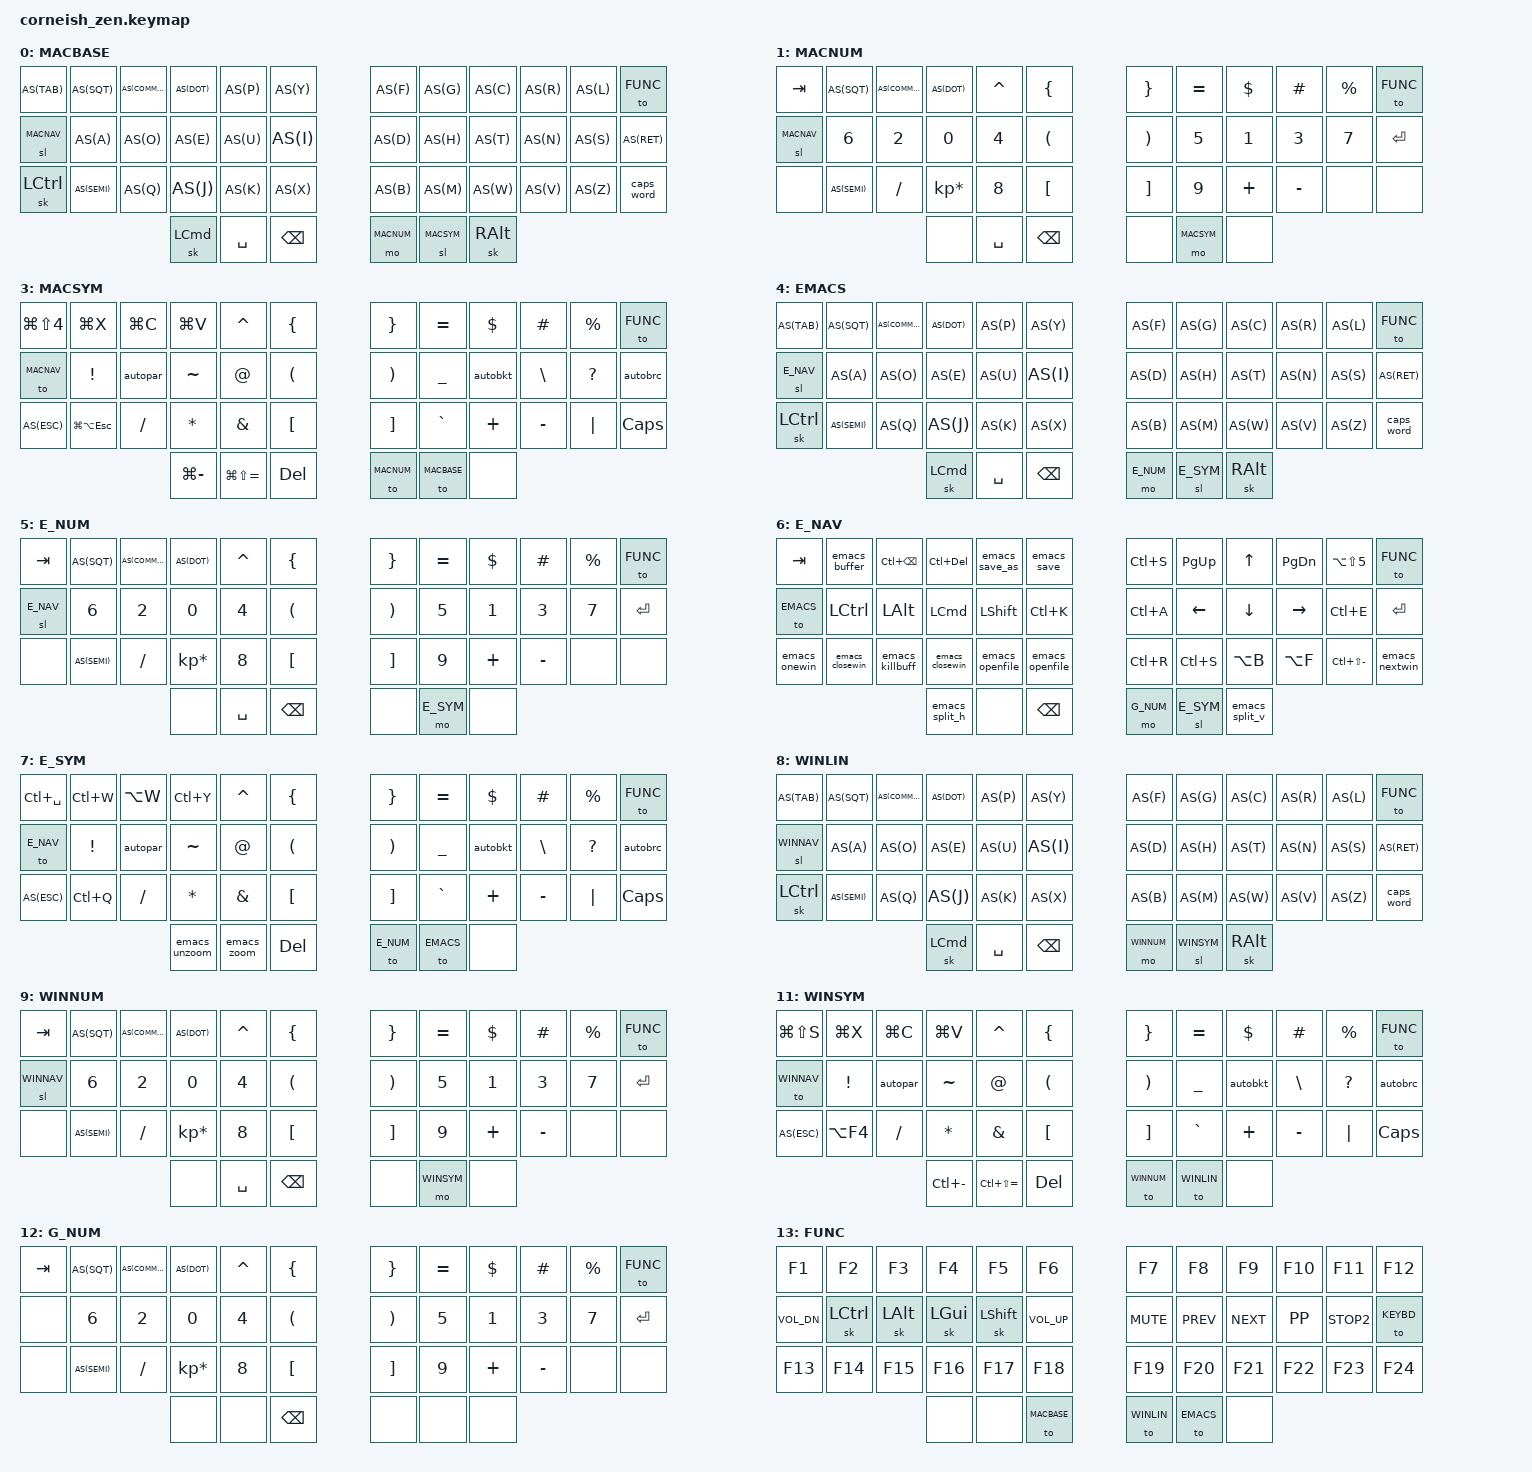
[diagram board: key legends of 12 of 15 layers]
/*
*
* Copyright (c) 2021 Darryl deHaan
* SPDX-License-Identifier: MIT
*
*/

#include <behaviors.dtsi>
#include <dt-bindings/zmk/keys.h>
#include <dt-bindings/zmk/bt.h>
#define MACBASE 0
#define MACNUM 1
#define MACNAV 2
#define MACSYM 3
#define EMACS 4
#define E_NUM 5
#define E_NAV 6
#define E_SYM 7
#define WINLIN 8
#define WINNUM 9
#define WINNAV 10
#define WINSYM 11
#define G_NUM 12
#define FUNC 13
#define KEYBD 14

#define AS(keycode) &as LS(keycode) keycode     // Autoshift Macro





/ {
  chosen {
    zmk,matrix_transform = &default_transform;
    //zmk,matrix_transform = &five_column_transform;
  };
};

 / {  // MACROS
     ZMK_MACRO(emacs_save,
        wait-ms = <30>;
        tap-ms = <40>;
        bindings = < &kp LC(X) &kp LC(S) >;
    )

     ZMK_MACRO(emacs_buffer,
        wait-ms = <30>;
        tap-ms = <40>;
        bindings = < &kp LC(X) &kp B >;
    )

     ZMK_MACRO(emacs_save_as,
        wait-ms = <30>;
        tap-ms = <40>;
        bindings = < &kp LC(X) &kp LC(W) >;
    )

     ZMK_MACRO(emacs_unzoom,
        wait-ms = <30>;
        tap-ms = <40>;
        bindings = < &kp LC(X) &kp LC(MINUS) &kp LC(G) >;
    )

     ZMK_MACRO(emacs_zoom,
        wait-ms = <30>;
        tap-ms = <40>;
        bindings = < &kp LC(X) &kp LC(LS(EQUAL)) &kp LC(G) >;
    )


     ZMK_MACRO(emacs_closewin,
        wait-ms = <30>;
        tap-ms = <40>;
        bindings = < &kp LC(X) &kp N0 >;
    )

     ZMK_MACRO(emacs_killbuff,
        wait-ms = <30>;
        tap-ms = <40>;
        bindings = < &kp LC(X) &kp K >;
    )

     ZMK_MACRO(emacs_openfile,
        wait-ms = <30>;
        tap-ms = <40>;
        bindings = < &kp LC(X) &kp LC(F) >;
    )

ZMK_MACRO(emacs_onewin,
wait-ms = <30>;
tap-ms = <40>;
bindings = < &kp LC(X) &kp N1 >;
)


     ZMK_MACRO(emacs_nextwin,
        wait-ms = <30>;
        tap-ms = <40>;
        bindings = < &kp LC(X) &kp O >;
    )

     ZMK_MACRO(emacs_split_h,
        wait-ms = <30>;
        tap-ms = <40>;
        bindings = < &kp LC(X) &kp N2 >;
    )

     ZMK_MACRO(win_del_line,
        wait-ms = <30>;
        tap-ms = <40>;
        bindings = < &kp LS(END) &kp DEL >;
    )



     ZMK_MACRO(emacs_split_v,
        wait-ms = <30>;
        tap-ms = <40>;
        bindings = < &kp LC(X) &kp N3 >;
    )



    ZMK_MACRO(autobrc,
        wait-ms = <30>;
        tap-ms = <40>;
        bindings = < &kp LBRC &kp RBRC &kp LEFT >;
    )

     ZMK_MACRO(autopar,
        wait-ms = <30>;
        tap-ms = <40>;
        bindings = < &kp LPAR &kp RPAR &kp LEFT  >;
    )

     ZMK_MACRO(autobkt,
        wait-ms = <30>;
        tap-ms = <40>;
        bindings = < &kp LBKT &kp RBKT &kp LEFT >;
    )

     ZMK_MACRO(vlog_assign,
        wait-ms = <30>;
        tap-ms = <40>;
        bindings = < &kp LT &kp EQUAL >;
    )

     

};


/ {

 behaviors {
        as: auto_shift {
            compatible = "zmk,behavior-hold-tap";
            label = "AUTO_SHIFT";
            #binding-cells = <2>;
            tapping_term_ms = <210>;
            quick_tap_ms = <0>;
            flavor = "tap-preferred";
            bindings = <&kp>, <&kp>;
        };
    };


        keymap {
                compatible = "zmk,keymap";

                macbase_layer {
                        label = "MACBASE"; // layer 0
// notes: i want the nav layer activated as momentary or one-shot, not toggle, unless sent there by another laye0r
//        func should be a 'to' switch to that layer, but will consider osl at a later time
//        num should be momentary switch over
//        sym should be one shot layer
// -----------------------------------------------------------------------------------------
// | TAB   |  '  |  ,   |  .    |  P  |  Y   |   |  F    |  G    |  C  |  R  |  L  | L:FNC |
// | L:NAV |  A  |  O   |  E    |  U  |  I   |   |  D    |  H    |  T  |  N  |  S  | RET   |
// | CTRL  |  ;  |  Q   |  J    |  K  |  X   |   |  B    |  M    |  W  |  V  |  Z  | CMD   |
//                      | LCTRL | SPC | BSPC |   | L:NUM | L:SYM | ALT |
   bindings = <
   AS(TAB)     AS(SQT)  AS(COMMA) AS(DOT)   AS(P)     AS(Y)      AS(F)      AS(G)    AS(C)   AS(R)   AS(L)    &to FUNC
   &sl MACNAV  AS(A)    AS(O)     AS(E)     AS(U)     AS(I)      AS(D)      AS(H)    AS(T)   AS(N)   AS(S)    AS(RET)
   &sk LCTRL     AS(SEMI) AS(Q)     AS(J)     AS(K)     AS(X)      AS(B)      AS(M)    AS(W)   AS(V)   AS(Z)    &caps_word
                        &sk LCMD &kp SPACE &kp BSPC &mo MACNUM &sl MACSYM &sk RALT
                        >;
                };
                macnum_layer {
                        label = "MACNUM"; // layer 1
// -----------------------------------------------------------------------------------------
// | TAB   |  '  |  ,  |  .     |  ^  | {    |   | }    | =     |  $   |  #  |  %   | L:FNC |
// | L:NAV |  6  |  2  |  0     |  4  | (    |   | )    | 5     |  1   |  3  |  7   | RET    |
// | NONE  |  ;  |  /  |  *     |  8  | [    |   | ]    | 9     |  +   |  -  | NONE | NONE   |
//                     | NONE   | SPC | BSPC |   | NONE | 3:SYM | NONE |
   bindings = <
   &kp TAB    AS(SQT)  AS(COMMA) AS(DOT)          &kp CARET   &kp LBRC    &kp RBRC   &kp EQUAL  &kp DLLR &kp HASH  &kp PRCNT &to FUNC
   &sl MACNAV &kp N6   &kp N2    &kp N0           &kp N4      &kp LPAR    &kp RPAR   &kp N5     &kp N1   &kp N3    &kp N7    &kp RET
   &none      AS(SEMI) &kp FSLH  &kp KP_MULTIPLY  &kp N8      &kp LBKT    &kp RBKT   &kp N9     &kp PLUS &kp MINUS &none     &none
                                 &none            &kp SPACE   &kp BSPC    &none      &mo MACSYM &none
                        >;
                };

                macnav_layer {
                        label ="MACNAV"; //layer 2
// -----------------------------------------------------------------------------------------
// | TAB    | BUFFER | DEL WORD LFT| DEL WORD RGT | SAVEAS  | SAVE   |  | FIND       | PAGEUP    | UP         | PAGEDOWN   | REPLACE | L:FUNC   |
// | L:BASE | LCTRL  | LALT        | LCMD         | LSHFT | DEL LINE |  | HOME       | LEFT      | DOWN       | RIGHT      | END     | ENTER    |
// | MAX    | MIN    | CLOSE       | MINIMIZE     | NEW   | OPEN     |  | FIND REV   | FIND FWD  | WORD LEFT  | WORD RIGHT | UNDO    | NEXT WIN |
//                                 | WIN LEFT     | SPC   | DEL      |  | L:NUM      | L:SYM     | WIN RIGHT  |
                        bindings = <
   &kp TAB       &kp LG(O)  &kp LA(BSPC)  &kp LS(LA(DEL))      &kp LG(S)   &kp LG(LS(S)) &kp LG(F)     &kp PG_UP    &kp UP                &kp PG_DN     &kp LC(K)     &to FUNC
   &to MACBASE   &kp LCTRL  &kp LALT      &kp LCMD             &kp LSHFT   &kp LC(K)     &kp LG(LEFT)  &kp LEFT     &kp DOWN              &kp RIGHT     &kp LG(RIGHT) &kp RET
   &kp LA(LG(H)) &kp LG(H)  &kp LG(W)     &kp LG(M)            &kp LG(O)   &kp LG(N)     &kp LG(G)     &kp LA(LEFT) &kp LA(RIGHT)         &kp LG(LS(G)) &kp LG(Z)     &kp LC(F3)
                    	                  &kp LG(LA(LC(LEFT))) &kp LG(SPC) &kp BSPC      &mo G_NUM     &sl MACSYM   &kp LG(LA(LC(RIGHT)))
                        >;
                };
		
                macsym_layer {
                        label = "MACSYM"; //layer 3
// -----------------------------------------------------------------------------------------
// | SNIP  | CUT  | COPY| PASTE| ^    | {   | | }     |  =     |  $    |  #  |  %    | L:FUNC | 
// | L:NAV | !    | ()  |  ~   | @    | (   | | )     |  _     |  []   |  \  |  ?    | {}     |
// | ESC   | QUIT | /   |  *   | &    | [   | | ]     |  `     |  +    |  -  |  PIPE | CAPS   |
//                      | UNZM | ZOOM | DEL | | L:NUM | L:BASE | NONE  |
                        bindings = <
   &kp LG(LS(N4)) &kp LG(X)        &kp LG(C) &kp LG(V) &kp CARET  &kp LBRC &kp RBRC    &kp EQUAL   &kp DLLR &kp HASH  &kp PRCNT  &to FUNC
   &to MACNAV    &kp EXCL         &autopar  &kp TILDE &kp AT     &kp LPAR &kp RPAR    &kp UNDER   &autobkt &kp BSLH  &kp QMARK  &autobrc
   AS(ESC)       &kp LG(LA(ESC)) &kp FSLH  &kp STAR  &kp AMPS   &kp LBKT &kp RBKT    &kp GRAVE   &kp PLUS &kp MINUS &kp PIPE   &kp CAPS  
                    	          &kp LG(MINUS) &kp  LG(LS(EQUAL)) &kp DEL  &to MACNUM  &to MACBASE &none
                        >;
                };

// insert emacs and windows keyboards here

                emacs_layer {
                      label = "EMACS"; // layer 4
// notes: i want the nav layer activated as momentary or one-shot, not toggle, unless sent there by another laye0r
//        func should be a 'to' switch to that layer, but will consider osl at a later time
//        num should be momentary switch over
//        sym should be one shot layer
// -----------------------------------------------------------------------------------------
// | TAB   |  '  |  ,   |  .    |  P  |  Y   |   |  F    |  G    |  C  |  R  |  L  | L:FNC |
// | L:NAV |  A  |  O   |  E    |  U  |  I   |   |  D    |  H    |  T  |  N  |  S  | RET   |
// | CTRL  |  ;  |  Q   |  J    |  K  |  X   |   |  B    |  M    |  W  |  V  |  Z  |CapsWord|
//                      | LCMD  | SPC | BSPC |   | L:NUM | L:SYM | ALT |
   bindings = <
   AS(TAB)     AS(SQT)  AS(COMMA) AS(DOT)   AS(P)     AS(Y)      AS(F)      AS(G)    AS(C)   AS(R)   AS(L)    &to FUNC
   &sl E_NAV   AS(A)    AS(O)     AS(E)     AS(U)     AS(I)      AS(D)      AS(H)    AS(T)   AS(N)   AS(S)    AS(RET)
   &sk LCTRL   AS(SEMI) AS(Q)     AS(J)     AS(K)     AS(X)      AS(B)      AS(M)    AS(W)   AS(V)   AS(Z)    &caps_word
                        &sk LCMD &kp SPACE &kp BSPC &mo E_NUM &sl E_SYM &sk RALT
                        >;
                };
                e_num_layer {
                        label = "E_NUM"; // layer 5
// -----------------------------------------------------------------------------------------
// | TAB   |  '  |  ,  |  .     |  ^  | {    |   | }    | =     |  $   |  #  |  %   | L:FNC |
// | L:NAV |  6  |  2  |  0     |  4  | (    |   | )    | 5     |  1   |  3  |  7   | RET    |
// | ---   |  ;  |  /  |  *     |  8  | [    |   | ]    | 9     |  +   |  -  | NONE | NONE   |
//                     | MACRO1 | SPC | BSPC |   | NONE | 3:SYM |MACRO2|
   bindings = <
   &kp TAB    AS(SQT)  AS(COMMA) AS(DOT)          &kp CARET   &kp LBRC    &kp RBRC   &kp EQUAL &kp DLLR &kp HASH  &kp PRCNT &to FUNC
   &sl E_NAV  &kp N6   &kp N2    &kp N0           &kp N4      &kp LPAR    &kp RPAR   &kp N5    &kp N1   &kp N3    &kp N7    &kp RET
   &none    AS(SEMI) &kp FSLH  &kp KP_MULTIPLY  &kp N8      &kp LBKT    &kp RBKT   &kp N9    &kp PLUS &kp MINUS &none     &none
                                 &none            &kp SPACE   &kp BSPC    &none      &mo E_SYM &none
                        >;
                };

                e_nav_layer {
                        label = "E_NAV"; //layer 6
// -----------------------------------------------------------------------------------------------------------------------------------------------
// | TAB    | BUFFER | DEL WORD LFT| DEL WORD RGT | SAVEAS| SAVE     |  | FIND       | PAGEUP    | UP         | PAGEDOWN   | REPLACE | L:FUNC   |
// | L:BASE | LCTRL  | LALT        | LCMD         | LSHFT | DEL LINE |  | HOME       | LEFT      | DOWN       | RIGHT      | END     | ENTER    |
// | MAX    | MIN    | CLOSE       | MINIMIZE         | NEW   | OPEN     |  | FIND REV   | FIND FWD  | WORD LEFT  | WORD RIGHT | UNDO    | NEXT WIN |
//                                 | WIN LEFT     | SPC   | DEL      |  | L:NUM      | L:SYM     | WIN RIGHT  |
                        bindings = <
   &kp TAB       &emacs_buffer     &kp LC(BSPC)    &kp LC(DEL)      &emacs_save_as   &emacs_save     &kp LC(S)     &kp PG_UP    &kp UP                &kp PG_DN  &kp LA(LS(5))      &to FUNC
   &to EMACS     &kp LCTRL         &kp LALT        &kp LCMD         &kp LSHFT        &kp LC(K)       &kp LC(A)     &kp LEFT     &kp DOWN              &kp RIGHT  &kp LC(E)          &kp RET
   &emacs_onewin   &emacs_closewin      &emacs_killbuff &emacs_closewin  &emacs_openfile  &emacs_openfile &kp LC(R)     &kp LC(S)    &kp LA(B)             &kp LA(F)  &kp LC(LS(MINUS))  &emacs_nextwin
                    	                           &emacs_split_h   &none            &kp BSPC        &mo G_NUM     &sl E_SYM    &emacs_split_v
						   >;
                };
		
                e_sym_layer {
                        label = "E_SYM"; //layer 7
// -----------------------------------------------------------------------------------------
// | MARK     | CUT  | COPY  | PASTE | ^       | {   | | }     |  =     |  $   |  #  |  %    | L:FUNC | 
// | L:NAV    | !    | ()    |  ~    | @       | (   | | )     |  _     |  []  |  \  |  ?    | {}     |
// | ESC      | QUIT | /     |  *    | &       | [   | | ]     |  `     |  +   |  -  |  PIPE | CAPS   |
//                           | UNZOOM| ZOOM    | DEL | | L:NUM | L:BASE | NONE |
                        bindings = <
   &kp LC(SPC)  &kp LC(W)  &kp LA(W) &kp LC(Y) &kp CARET  &kp LBRC &kp RBRC    &kp EQUAL   &kp DLLR &kp HASH  &kp PRCNT  &to FUNC
   &to E_NAV    &kp EXCL   &autopar  &kp TILDE &kp AT     &kp LPAR &kp RPAR    &kp UNDER   &autobkt &kp BSLH  &kp QMARK  &autobrc
   AS(ESC)      &kp LC(Q)  &kp FSLH  &kp STAR  &kp AMPS   &kp LBKT &kp RBKT    &kp GRAVE   &kp PLUS &kp MINUS &kp PIPE   &kp CAPS
                    	             &emacs_unzoom    &emacs_zoom  &kp DEL  &to E_NUM   &to EMACS   &none
                        >;
                };

                winlin_layer {
                        label = "WINLIN"; // layer 8
// notes: i want the nav layer activated as momentary or one-shot, not toggle, unless sent there by another laye0r
//        func should be a 'to' switch to that layer, but will consider osl at a later time
//        num should be momentary switch over
//        sym should be one shot layer
// -----------------------------------------------------------------------------------------
// | TAB   |  '  |  ,   |  .    |  P  |  Y   |   |  F    |  G    |  C  |  R  |  L  | L:FNC |
// | L:NAV |  A  |  O   |  E    |  U  |  I   |   |  D    |  H    |  T  |  N  |  S  | RET   |
// | LCTRL |  ;  |  Q   |  J    |  K  |  X   |   |  B    |  M    |  W  |  V  |  Z  |Capsword|
//                      | LCMD  | SPC | BSPC |   | L:NUM | L:SYM | ALT |
   bindings = <
   AS(TAB)     AS(SQT)  AS(COMMA) AS(DOT)   AS(P)     AS(Y)      AS(F)      AS(G)    AS(C)   AS(R)   AS(L)    &to FUNC
   &sl WINNAV  AS(A)    AS(O)     AS(E)     AS(U)     AS(I)      AS(D)      AS(H)    AS(T)   AS(N)   AS(S)    AS(RET)
   &sk LCTRL   AS(SEMI) AS(Q)     AS(J)     AS(K)     AS(X)      AS(B)      AS(M)    AS(W)   AS(V)   AS(Z)    &caps_word
                        &sk LCMD  &kp SPACE &kp BSPC &mo WINNUM &sl WINSYM &sk RALT
                        >;
                };
                winnum_layer {
                        label = "WINNUM"; // layer 9
// -----------------------------------------------------------------------------------------
// | TAB   |  '  |  ,  |  .     |  ^  | {    |   | }    | =     |  $   |  #  |  %   | L:FNC |
// | L:NAV |  6  |  2  |  0     |  4  | (    |   | )    | 5     |  1   |  3  |  7   | RET    |
// |       |  ;  |  /  |  *     |  8  | [    |   | ]    | 9     |  +   |  -  | NONE | NONE   |
//                     | MACRO1 | SPC | BSPC |   | NONE | 3:SYM |MACRO2|
   bindings = <
   &kp TAB    AS(SQT)  AS(COMMA) AS(DOT)          &kp CARET   &kp LBRC    &kp RBRC   &kp EQUAL &kp DLLR &kp HASH  &kp PRCNT &to FUNC
   &sl WINNAV &kp N6   &kp N2    &kp N0           &kp N4      &kp LPAR    &kp RPAR   &kp N5    &kp N1   &kp N3    &kp N7    &kp RET
   &none      AS(SEMI) &kp FSLH  &kp KP_MULTIPLY  &kp N8      &kp LBKT    &kp RBKT   &kp N9    &kp PLUS &kp MINUS &none     &none
                                 &none            &kp SPACE   &kp BSPC    &none      &mo WINSYM &none
                        >;
                };

                winnav_layer {
                        label = "WINNAV"; //layer 10
// -----------------------------------------------------------------------------------------
// | TAB    | BUFFER | DEL WORD LFT| DEL WORD RGT | SAVEAS  | SAVE   |  | FIND       | PAGEDOWN  | UP         | PAGEUP     | REPLACE | L:FUNC   |
// | L:BASE | LCTRL  | LALT        | LCMD         | LSHFT | DEL LINE |  | HOME       | LEFT      | DOWN       | RIGHT      | END     | ENTER    |
// | MAX    | MIN    | CLOSE       | MINIMIZE     | NEW   | OPEN     |  | FIND REV   | FIND FWD  | WORD LEFT  | WORD RIGHT | UNDO    | NEXT WIN |
//                                 | WIN LEFT     | SPC   | DEL      |  | L:NUM      | L:SYM     | WIN RIGHT  |
                        bindings = <
   AS(TAB)       &kp LC(O)         &kp LC(BSPC)  &kp LC(DEL)          &kp F12     &kp LC(S)     &kp LC(F)          &kp PG_UP    &kp UP                &kp PG_DN     &kp LC(H)     &to FUNC
   &to WINLIN    &kp LCTRL         &kp LALT      &kp LCMD             &kp LSHFT   &win_del_line &kp HOME           &kp LEFT     &kp DOWN              &kp RIGHT     &kp END       &kp RET
   &kp LG(UP)    &kp LG(DOWN)      &kp LC(W)     &kp LG(DOWN)         &kp LC(N)   &kp LG(O)     &kp LC(LS(G))     &kp F3       &kp LC(LEFT)          &kp LC(RIGHT) &kp LC(Z)     &kp LA(LC(TAB))
                    	                         &kp LG(LA(LC(LEFT))) &kp LG(SPC) &kp BSPC      &mo G_NUM     &sl WINSYM   &kp LG(LA(LC(RIGHT)))
                        >;
                };
		
                winsym_layer {
                        label = "WINSYM"; //layer 11
// -----------------------------------------------------------------------------------------
// | SNIP     | CUT  | COPY  | PASTE | ^       | {   | | }     |  =     |  $   |  #  |  %    | L:FUNC | 
// | L:NAV    | !    | ()    |  ~    | @       | (   | | )     |  _     |  []  |  \  |  ?    | {}     |
// | ESC      | QUIT | /     |  *    | &       | [   | | ]     |  `     |  +   |  -  |  PIPE | CAPS   |
//                           | UNZM  | ZOOM    | DEL | | L:NUM | L:BASE | NONE |
                        bindings = <
   &kp LG(LS(S)) &kp LG(X)  &kp LG(C) &kp LG(V)     &kp CARET  &kp LBRC &kp RBRC    &kp EQUAL   &kp DLLR &kp HASH  &kp PRCNT  &to FUNC
   &to WINNAV    &kp EXCL   &autopar  &kp TILDE     &kp AT     &kp LPAR &kp RPAR    &kp UNDER   &autobkt &kp BSLH  &kp QMARK  &autobrc
   AS(ESC)       &kp LA(F4) &kp FSLH  &kp STAR      &kp AMPS   &kp LBKT &kp RBKT    &kp GRAVE   &kp PLUS &kp MINUS &kp PIPE   &kp CAPS
                    	              &kp LC(MINUS) &kp LC(LS(EQUAL)) &kp DEL  &to WINNUM   &to WINLIN   &none
                        >;
                };
                g_num_layer {
                        label = "G_NUM"; // layer 12
// -----------------------------------------------------------------------------------------
// | TAB  |  '  |  ,  |  .     |  ^  | {    |   | }    | =     |  $   |  #  |  %   | L:FNC |
// | NONE |  6  |  2  |  0     |  4  | (    |   | )    | 5     |  1   |  3  |  7   | RET    |
// | NONE |  ;  |  /  |  *     |  8  | [    |   | ]    | 9     |  +   |  -  | NONE | NONE   |
//                     | MACRO1 | SPC | BSPC |   | NONE | 3:SYM |MACRO2|
   bindings = <
   &kp TAB    AS(SQT)  AS(COMMA) AS(DOT)          &kp CARET   &kp LBRC    &kp RBRC   &kp EQUAL &kp DLLR &kp HASH  &kp PRCNT &to FUNC
   &none      &kp N6   &kp N2    &kp N0           &kp N4      &kp LPAR    &kp RPAR   &kp N5    &kp N1   &kp N3    &kp N7    &kp RET
   &none      AS(SEMI) &kp FSLH  &kp KP_MULTIPLY  &kp N8      &kp LBKT    &kp RBKT   &kp N9    &kp PLUS &kp MINUS &none     &none
                                 &none   &none    &kp BSPC    &none      &none     &none
                        >;
                };

                func_layer {
                        label = "FUNC"; //layer 13
// -----------------------------------------------------------------------------------------
// |  F1  |  F2  |  F3  | F4   | F5   |  F6   |  F7   |  F8      | F9  | F10 | F11 | F12  |  
// | VOLDN| LCTRL| LOPT | LCMD | LSHFT| VOLUP |  MUTE |  PREV    | NEXT| PLAY| STOP| KEYBD|
// | F13  | F14  | F15  | F16  | F17  | F18   |  F19  |  F20     | F21 | F22 | F23 |  F24 |  
//                      | NONE | NONE |MACBASE|WINBASE| EMACSBASE| NONE|
                        bindings = <
   &kp F1       &kp F2    &kp F3   &kp F4   &kp F5    &kp F6       &kp F7     &kp F8     &kp F9     &kp F10  &kp F11     &kp F12
   &kp K_VOL_DN &sk LCTRL &sk LALT &sk LGUI &sk LSHFT &kp K_VOL_UP &kp K_MUTE &kp K_PREV &kp K_NEXT &kp K_PP &kp K_STOP2 &to KEYBD
   &kp F13      &kp F14   &kp F15  &kp F16  &kp F17   &kp F18      &kp F19    &kp F20    &kp F21    &kp F22  &kp F23     &kp F24
                    	           &none    &none     &to MACBASE  &to WINLIN &to EMACS  &none
                        >;
                };


                keybd_layer {
                        label = "KEYBD"; //layer 14
			
// -----------------------------------------------------------------------------------------
// |  BT1  |  BT2   |  BT3   | BT4    | BTPREV   | BT:NEXT  |  BTCLR    |  NONE   |  NONE   |  NONE    |  NONE |  TO:FUNC  |  
// | NONE  |  NONE  |  NONE  |  NONE  | NONE     | NONE     |  NONE     |  NONE   |  NONE   |  NONE    |  NONE |  NONE     |  
// | NONE  |  NONE  |  NONE  |  NONE  | NONE     | NONE     |  NONE     |  NONE   |  NONE   |  NONE    |  NONE |  RESET    |  
//                  |  NONE  | NONE   | MACBASE  | WINBASE  | EMACSBASE | NONE    |
                        bindings = <
   &bt BT_SEL 0  &bt BT_SEL 1 &bt BT_SEL 2 &bt BT_SEL 3  &bt BT_PRV &bt BT_NXT &bt BT_CLR  &none   &none &none  &none &to FUNC 
   &none         &none        &none        &none         &none      &none      &none       &none   &none &none  &none &none
   &none         &none        &none        &none         &none      &none      &none       &none   &none &none  &none &none
                    	                   &none         &none      &to MACBASE     &to WINLIN       &to EMACS   &none
                        >;
                }; //keybd_layer
       
        }; //keymap
	
}; //big module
